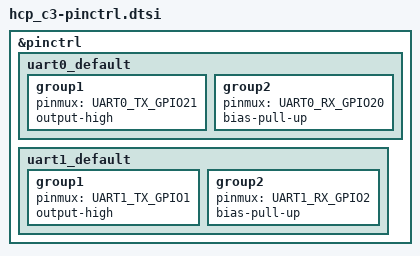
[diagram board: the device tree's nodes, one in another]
/*
 * HCP ESP32-C3 pin control. Console UART (uart0) + Modbus UART (uart1, TTL).
 * Copyright (c) 2026 maybetaken
 *
 * SPDX-License-Identifier: Apache-2.0
 */

#include <zephyr/dt-bindings/pinctrl/esp-pinctrl-common.h>
#include <zephyr/dt-bindings/pinctrl/esp32c3-pinctrl.h>
#include <zephyr/dt-bindings/pinctrl/esp32c3-gpio-sigmap.h>

&pinctrl {
	uart0_default: uart0_default {
		group1 {
			pinmux = <UART0_TX_GPIO21>;
			output-high;
		};
		group2 {
			pinmux = <UART0_RX_GPIO20>;
			bias-pull-up;
		};
	};

	uart1_default: uart1_default {
		group1 {
			pinmux = <UART1_TX_GPIO1>;
			output-high;
		};
		group2 {
			pinmux = <UART1_RX_GPIO2>;
			bias-pull-up;
		};
	};
};
